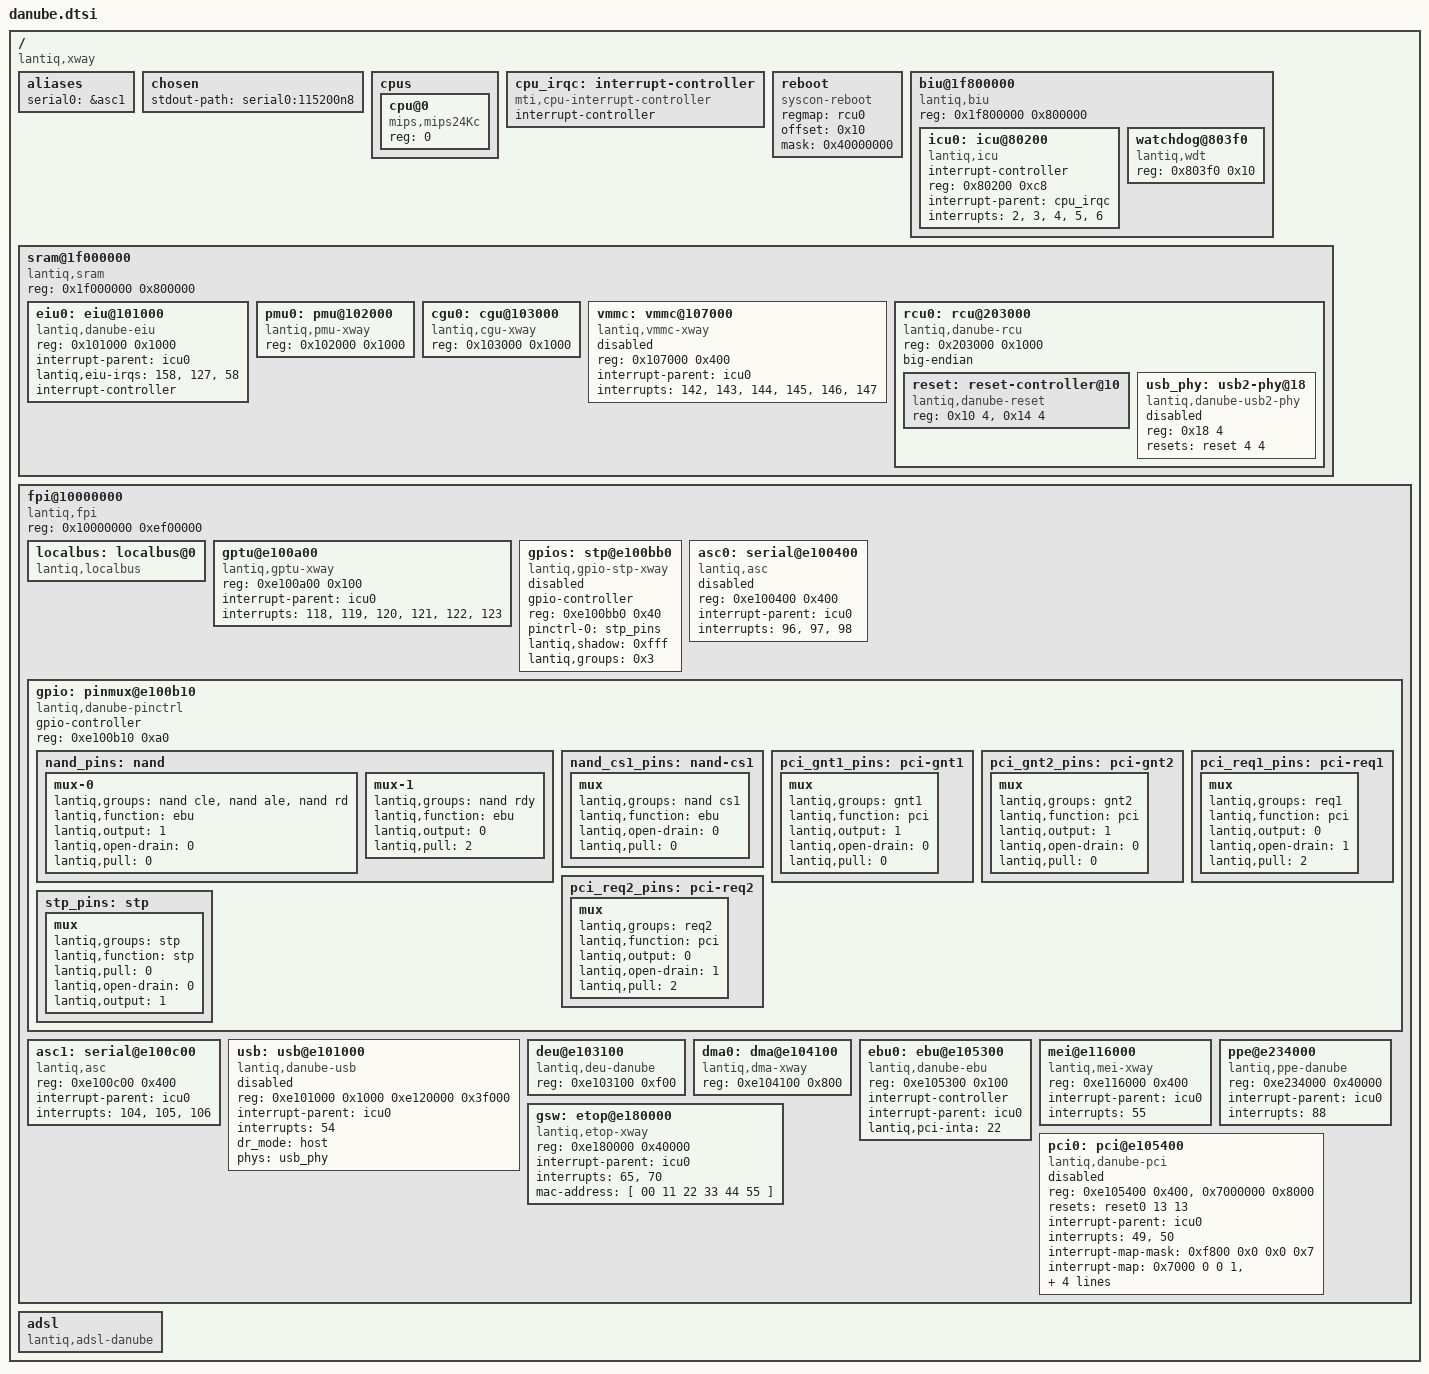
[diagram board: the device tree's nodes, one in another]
/dts-v1/;

#include <dt-bindings/gpio/gpio.h>
#include <dt-bindings/interrupt-controller/irq.h>

/ {
	#address-cells = <1>;
	#size-cells = <1>;
	compatible = "lantiq,xway", "lantiq,danube";

	aliases {
		serial0 = &asc1;
	};

	chosen {
		stdout-path = "serial0:115200n8";
	};

	cpus {
		#address-cells = <1>;
		#size-cells = <0>;

		cpu@0 {
			compatible = "mips,mips24Kc";
			reg = <0>;
		};
	};

	cpu_irqc: interrupt-controller {
		compatible = "mti,cpu-interrupt-controller";

		interrupt-controller;
		#interrupt-cells = <1>;
	};

	reboot {
		compatible = "syscon-reboot";

		regmap = <&rcu0>;
		offset = <0x10>;
		mask = <0x40000000>;
	};

	biu@1f800000 {
		#address-cells = <1>;
		#size-cells = <1>;
		compatible = "lantiq,biu", "simple-bus";
		reg = <0x1f800000 0x800000>;
		ranges = <0x0 0x1f800000 0x7fffff>;

		icu0: icu@80200 {
			#interrupt-cells = <1>;
			interrupt-controller;
			compatible = "lantiq,icu";
			/*
			 * There is a second ICU, but the SoC is not SMP
			 * capable.
			 */
			reg = <0x80200 0xc8>;
			interrupt-parent = <&cpu_irqc>;
			interrupts = <2>, <3>, <4>, <5>, <6>;
		};

		watchdog@803f0 {
			compatible = "lantiq,wdt";
			reg = <0x803f0 0x10>;
		};
	};

	sram@1f000000 {
		#address-cells = <1>;
		#size-cells = <1>;
		compatible = "lantiq,sram", "simple-bus";
		reg = <0x1f000000 0x800000>;
		ranges = <0x0 0x1f000000 0x7fffff>;

		eiu0: eiu@101000 {
			compatible = "lantiq,danube-eiu", "lantiq,xway-eiu";
			reg = <0x101000 0x1000>;
			interrupt-parent = <&icu0>;
			lantiq,eiu-irqs = <158>, <127>, <58>;
			interrupt-controller;
			#interrupt-cells = <1>;
		};

		pmu0: pmu@102000 {
			compatible = "lantiq,pmu-xway";
			reg = <0x102000 0x1000>;
		};

		cgu0: cgu@103000 {
			compatible = "lantiq,cgu-xway";
			reg = <0x103000 0x1000>;
			#clock-cells = <1>;
		};

		vmmc: vmmc@107000 {
			status = "disabled";
			compatible = "lantiq,vmmc-xway";
			reg = <0x107000 0x400>;
			interrupt-parent = <&icu0>;
			interrupts = <142>, <143>, <144>, <145>, <146>, <147>;
		};

		rcu0: rcu@203000 {
			#address-cells = <1>;
			#size-cells = <1>;
			compatible = "lantiq,danube-rcu", "simple-mfd", "syscon";
			reg = <0x203000 0x1000>;
			ranges = <0x0 0x203000 0x100>;
			big-endian;

			reset: reset-controller@10 {
				compatible = "lantiq,danube-reset";
				reg = <0x10 4>, <0x14 4>;

				#reset-cells = <2>;
			};

			usb_phy: usb2-phy@18 {
				compatible = "lantiq,danube-usb2-phy";
				reg = <0x18 4>;
				status = "disabled";

				resets = <&reset 4 4>;
				reset-names = "ctrl";
				#phy-cells = <0>;
			};
		};
	};

	fpi@10000000 {
		#address-cells = <1>;
		#size-cells = <1>;
		compatible = "lantiq,fpi", "simple-bus";
		ranges = <0x0 0x10000000 0xeefffff>;
		reg = <0x10000000 0xef00000>;

		localbus: localbus@0 {
			#address-cells = <2>;
			#size-cells = <1>;
			ranges = <0 0 0x0 0x3ffffff /* addrsel0 */
				1 0 0x4000000 0x4000010>; /* addsel1 */
			compatible = "lantiq,localbus", "simple-bus";
		};

		gptu@e100a00 {
			compatible = "lantiq,gptu-xway";
			reg = <0xe100a00 0x100>;
			interrupt-parent = <&icu0>;
			interrupts = <118>, <119>, <120>, <121>, <122>, <123>;
		};

		gpios: stp@e100bb0 {
			#gpio-cells = <2>;
			compatible = "lantiq,gpio-stp-xway";
			gpio-controller;
			reg = <0xe100bb0 0x40>;

			pinctrl-0 = <&stp_pins>;
			pinctrl-names = "default";

			lantiq,shadow = <0xfff>;
			lantiq,groups = <0x3>;
			status = "disabled";
		};

		asc0: serial@e100400 {
			compatible = "lantiq,asc";
			reg = <0xe100400 0x400>;
			interrupt-parent = <&icu0>;
			interrupts = <96>, <97>, <98>;
			status = "disabled";
		};

		gpio: pinmux@e100b10 {
			compatible = "lantiq,danube-pinctrl";
			#gpio-cells = <2>;
			gpio-controller;
			reg = <0xe100b10 0xa0>;

			nand_pins: nand {
				mux-0 {
					lantiq,groups = "nand cle", "nand ale",
							"nand rd";
					lantiq,function = "ebu";
					lantiq,output = <1>;
					lantiq,open-drain = <0>;
					lantiq,pull = <0>;
				};
				mux-1 {
					lantiq,groups = "nand rdy";
					lantiq,function = "ebu";
					lantiq,output = <0>;
					lantiq,pull = <2>;
				};
			};

			nand_cs1_pins: nand-cs1 {
				mux {
					lantiq,groups = "nand cs1";
					lantiq,function = "ebu";
					lantiq,open-drain = <0>;
					lantiq,pull = <0>;
				};
			};

			pci_gnt1_pins: pci-gnt1 {
				mux {
					lantiq,groups = "gnt1";
					lantiq,function = "pci";
					lantiq,output = <1>;
					lantiq,open-drain = <0>;
					lantiq,pull = <0>;
				};
			};

			pci_gnt2_pins: pci-gnt2 {
				mux {
					lantiq,groups = "gnt2";
					lantiq,function = "pci";
					lantiq,output = <1>;
					lantiq,open-drain = <0>;
					lantiq,pull = <0>;
				};
			};

			pci_req1_pins: pci-req1 {
				mux {
					lantiq,groups = "req1";
					lantiq,function = "pci";
					lantiq,output = <0>;
					lantiq,open-drain = <1>;
					lantiq,pull = <2>;
				};
			};

			pci_req2_pins: pci-req2 {
				mux {
					lantiq,groups = "req2";
					lantiq,function = "pci";
					lantiq,output = <0>;
					lantiq,open-drain = <1>;
					lantiq,pull = <2>;
				};
			};

			stp_pins: stp {
				mux {
					lantiq,groups = "stp";
					lantiq,function = "stp";
					lantiq,pull = <0>;
					lantiq,open-drain = <0>;
					lantiq,output = <1>;
				};
			};
		};

		asc1: serial@e100c00 {
			compatible = "lantiq,asc";
			reg = <0xe100c00 0x400>;
			interrupt-parent = <&icu0>;
			interrupts = <104>, <105>, <106>;
		};

		usb: usb@e101000 {
			compatible = "lantiq,danube-usb";
			reg = <0xe101000 0x1000
				0xe120000 0x3f000>;
			interrupt-parent = <&icu0>;
			interrupts = <54>;
			dr_mode = "host";
			phys = <&usb_phy>;
			phy-names = "usb2-phy";
			status = "disabled";
		};

		deu@e103100 {
			compatible = "lantiq,deu-danube";
			reg = <0xe103100 0xf00>;
		};

		dma0: dma@e104100 {
			compatible = "lantiq,dma-xway";
			reg = <0xe104100 0x800>;
		};

		ebu0: ebu@e105300 {
			compatible = "lantiq,danube-ebu";
			reg = <0xe105300 0x100>;
			interrupt-controller;
			#interrupt-cells = <2>;
			interrupt-parent = <&icu0>;
			lantiq,pci-inta = <22>;
		};

		mei@e116000 {
			compatible = "lantiq,mei-xway";
			reg = <0xe116000 0x400>;
			interrupt-parent = <&icu0>;
			interrupts = <55>;
		};

		gsw: etop@e180000 {
			compatible = "lantiq,etop-xway";
			reg = <0xe180000 0x40000>;
			interrupt-parent = <&icu0>;
			interrupts = <65>, <70>;
			mac-address = [ 00 11 22 33 44 55 ];
		};

		ppe@e234000 {
			compatible = "lantiq,ppe-danube";
			reg = <0xe234000 0x40000>;
			interrupt-parent = <&icu0>;
			interrupts = <88>;
		};

		pci0: pci@e105400 {
			compatible = "lantiq,danube-pci", "lantiq,xway-pci";

			reg = <0xe105400 0x400>, <0x7000000 0x8000>;
			reg-names = "ctrl", "config";

			resets = <&reset0 13 13>;

			interrupt-parent = <&icu0>;
			interrupts = <49>, <50>;
			interrupt-names = "ir", "wake";

			#address-cells = <3>;
			#size-cells = <2>;

			#interrupt-cells = <1>;
			interrupt-map-mask = <0xf800 0x0 0x0 0x7>;
			interrupt-map = <0x7000 0 0 1 &ebu0 0 IRQ_TYPE_LEVEL_LOW>; /* slot 14 */

			bus-range = <0x0 0xf>;
			ranges = <0x02000000 0 0x18000000 0x8000000 0 0x2000000>;

			device_type = "pci";

			lantiq,bus-clock = <33333333>;
			req-mask = <0x1>; /* GNT1 */

			status = "disabled";
		};
	};

	adsl {
		compatible = "lantiq,adsl-danube";
	};
};
